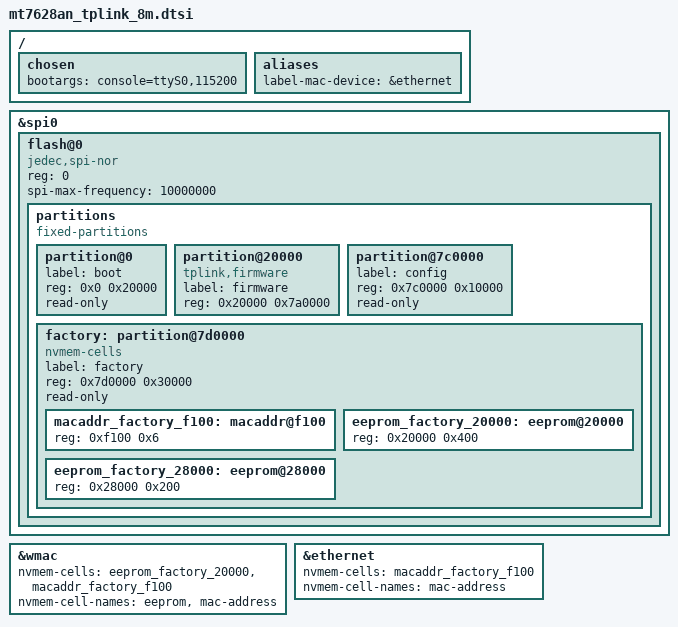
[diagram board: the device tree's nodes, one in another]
#include "mt7628an.dtsi"

#include <dt-bindings/input/input.h>
#include <dt-bindings/gpio/gpio.h>

/ {
	chosen {
		bootargs = "console=ttyS0,115200";
	};

	aliases {
		label-mac-device = &ethernet;
	};
};

&spi0 {
	status = "okay";

	flash@0 {
		compatible = "jedec,spi-nor";
		reg = <0>;
		spi-max-frequency = <10000000>;

		partitions {
			compatible = "fixed-partitions";
			#address-cells = <1>;
			#size-cells = <1>;

			partition@0 {
				label = "boot";
				reg = <0x0 0x20000>;
				read-only;
			};

			partition@20000 {
				compatible = "tplink,firmware";
				label = "firmware";
				reg = <0x20000 0x7a0000>;
			};

			partition@7c0000 {
				label = "config";
				reg = <0x7c0000 0x10000>;
				read-only;
			};

			factory: partition@7d0000 {
				compatible = "nvmem-cells";
				label = "factory";
				reg = <0x7d0000 0x30000>;
				#address-cells = <1>;
				#size-cells = <1>;
				read-only;

				macaddr_factory_f100: macaddr@f100 {
					reg = <0xf100 0x6>;
				};

				eeprom_factory_20000: eeprom@20000 {
					reg = <0x20000 0x400>;
				};

				eeprom_factory_28000: eeprom@28000 {
					reg = <0x28000 0x200>;
				};
			};
		};
	};
};

&wmac {
	status = "okay";

	nvmem-cells = <&eeprom_factory_20000>, <&macaddr_factory_f100>;
	nvmem-cell-names = "eeprom", "mac-address";
};

&ethernet {
	nvmem-cells = <&macaddr_factory_f100>;
	nvmem-cell-names = "mac-address";
};
